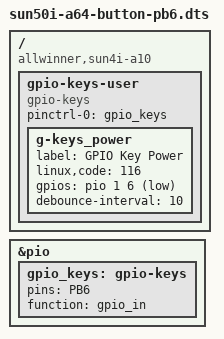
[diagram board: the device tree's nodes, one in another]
/*
* DevDotNet.ORG <anton@devdotnet.org>
*
* MIT License
* 
* Device: Digital Push Button, https://www.dfrobot.com/product-73.html
* Module      Connector
* Control    ->  PB6
*/

/dts-v1/;
/plugin/;

/ {
	compatible = "allwinner,sun4i-a10", "allwinner,sun7i-a20", "allwinner,sun8i-h3", "allwinner,sun50i-a64", "allwinner,sun50i-h5";
	
	fragment@0 {
		target = <&pio>;
		__overlay__ {
			gpio_keys: gpio-keys {
				pins = "PB6";
				/* for many: pins = "PA7","PA8","PA9","PA10","PA21"; */
				function = "gpio_in";
				/*bias-pull-up;*/
			};
		};
	};

	fragment@1 {
		target-path = "/";
		__overlay__ {
			gpio-keys-user {				
				compatible = "gpio-keys";
				//autorepeat;
				pinctrl-names = "default";
				pinctrl-0 = <&gpio_keys>;

				g-keys_power {
					label = "GPIO Key Power";
					linux,code = <116>; /* KEY_POWER, see include/uapi/linux/input-event-codes.h */					
					gpios = <&pio 1 6 1>; /* PA10 GPIO_ACTIVE_LOW */
					debounce-interval= <10>; /* Debouncing interval time in milliseconds. defaults to 5 */										
				};
			};
		};
	};
};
